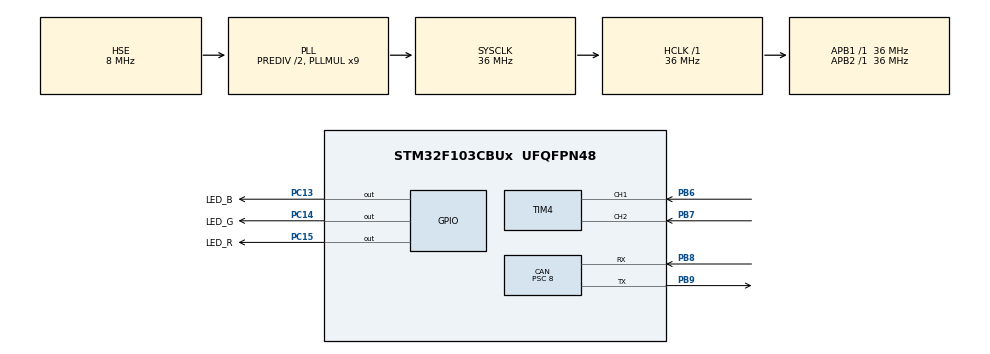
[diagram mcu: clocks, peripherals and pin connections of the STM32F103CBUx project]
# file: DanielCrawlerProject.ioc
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CAN.BS1=CAN_BS1_3TQ
CAN.BS2=CAN_BS2_5TQ
CAN.CalculateBaudRate=500000
CAN.CalculateTimeBit=1999.99
CAN.CalculateTimeQuantum=222.22222222222223
CAN.Prescaler=8
Mcu.Family=STM32F1
Mcu.Name=STM32F103CBUx
Mcu.Package=UFQFPN48
Mcu.UserConstants=MAX_ENCODER_COUNT,2000
NVIC.PriorityGroup=NVIC_PRIORITYGROUP_4
NVIC.TIM1_UP_IRQn=true\:4\:0\:true\:false\:true\:true\:true
NVIC.USB_LP_CAN1_RX0_IRQn=true\:0\:0\:false\:false\:true\:true\:true
PA13.Mode=Serial_Wire
PA13.Signal=SYS_JTMS-SWDIO
PA14.Mode=Serial_Wire
PA14.Signal=SYS_JTCK-SWCLK
PB6.Signal=S_TIM4_CH1
PB7.Signal=S_TIM4_CH2
PB8.Mode=CAN_Activate
PB8.Signal=CAN_RX
PB9.Mode=CAN_Activate
PB9.Signal=CAN_TX
PC13-TAMPER-RTC.GPIO_Label=LED_B
PC13-TAMPER-RTC.PinState=GPIO_PIN_RESET
PC13-TAMPER-RTC.Signal=GPIO_Output
PC14-OSC32_IN.GPIO_Label=LED_G
PC14-OSC32_IN.PinState=GPIO_PIN_RESET
PC14-OSC32_IN.Signal=GPIO_Output
PC15-OSC32_OUT.GPIO_Label=LED_R
PC15-OSC32_OUT.PinState=GPIO_PIN_RESET
PC15-OSC32_OUT.Signal=GPIO_Output
PD0-OSC_IN.Mode=HSE-External-Oscillator
PD0-OSC_IN.Signal=RCC_OSC_IN
PD1-OSC_OUT.Mode=HSE-External-Oscillator
PD1-OSC_OUT.Signal=RCC_OSC_OUT
ProjectManager.HeapSize=0x200
ProjectManager.StackSize=0x400
ProjectManager.TargetToolchain=STM32CubeIDE
RCC.AHBFreq_Value=36000000
RCC.APB1Freq_Value=36000000
RCC.APB1TimFreq_Value=36000000
RCC.APB2Freq_Value=36000000
RCC.APB2TimFreq_Value=36000000
RCC.HCLKFreq_Value=36000000
RCC.HSEDivPLL=RCC_HSE_PREDIV_DIV2
RCC.PLLMUL=RCC_PLL_MUL9
RCC.PLLSourceVirtual=RCC_PLLSOURCE_HSE
RCC.SYSCLKFreq_VALUE=36000000
RCC.SYSCLKSource=RCC_SYSCLKSOURCE_PLLCLK
RCC.USBFreq_Value=36000000
SH.S_TIM4_CH1.0=TIM4_CH1,Encoder_Interface
SH.S_TIM4_CH2.0=TIM4_CH2,Encoder_Interface
TIM1.Period=5000-1
TIM1.Prescaler=36-1
TIM4.EncoderMode=TIM_ENCODERMODE_TI12
TIM4.Period=MAX_ENCODER_COUNT
VP_TIM1_VS_ClockSourceINT.Mode=Internal
board=custom

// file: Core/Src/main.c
/* USER CODE BEGIN Header */
/**
  ******************************************************************************
  * @file           : main.c
  * @brief          : Main program body
  ******************************************************************************
  * @attention
  *
  * <h2><center>&copy; Copyright (c) 2020 STMicroelectronics.
  * All rights reserved.</center></h2>
  *
  * This software component is licensed by ST under BSD 3-Clause license,
  * the "License"; You may not use this file except in compliance with the
  * License. You may obtain a copy of the License at:
  *                        opensource.org/licenses/BSD-3-Clause
  *
  ******************************************************************************
  */
/* USER CODE END Header */
#include "main.h"
#include "can.h"
#include "tim.h"
#include "gpio.h"

/* USER CODE BEGIN Includes */
#include "cppmain.hpp"

/* USER CODE END Includes */

void SystemClock_Config(void);

int main(void)
{

  /* MCU Configuration--------------------------------------------------------*/

  /* Reset of all peripherals, Initializes the Flash interface and the Systick. */
  HAL_Init();

  /* Configure the system clock */
  SystemClock_Config();

  /* Initialize all configured peripherals */
  MX_GPIO_Init();
  MX_TIM1_Init();
  MX_TIM4_Init();
  MX_CAN_Init();
  /* USER CODE BEGIN 2 */
  setup();

  /* USER CODE END 2 */

  /* Infinite loop */
  /* USER CODE BEGIN WHILE */
  while (1)
  {
      loop();
    /* USER CODE END WHILE */

  }
}

void SystemClock_Config(void)
{
  RCC_OscInitTypeDef RCC_OscInitStruct = {0};
  RCC_ClkInitTypeDef RCC_ClkInitStruct = {0};

  /** Initializes the RCC Oscillators according to the specified parameters
  * in the RCC_OscInitTypeDef structure.
  */
  RCC_OscInitStruct.OscillatorType = RCC_OSCILLATORTYPE_HSE;
  RCC_OscInitStruct.HSEState = RCC_HSE_ON;
  RCC_OscInitStruct.HSEPredivValue = RCC_HSE_PREDIV_DIV2;
  RCC_OscInitStruct.HSIState = RCC_HSI_ON;
  RCC_OscInitStruct.PLL.PLLState = RCC_PLL_ON;
  RCC_OscInitStruct.PLL.PLLSource = RCC_PLLSOURCE_HSE;
  RCC_OscInitStruct.PLL.PLLMUL = RCC_PLL_MUL9;
  if (HAL_RCC_OscConfig(&RCC_OscInitStruct) != HAL_OK)
  {
    Error_Handler();
  }
  /** Initializes the CPU, AHB and APB buses clocks
  */
  RCC_ClkInitStruct.ClockType = RCC_CLOCKTYPE_HCLK|RCC_CLOCKTYPE_SYSCLK
                              |RCC_CLOCKTYPE_PCLK1|RCC_CLOCKTYPE_PCLK2;
  RCC_ClkInitStruct.SYSCLKSource = RCC_SYSCLKSOURCE_PLLCLK;
  RCC_ClkInitStruct.AHBCLKDivider = RCC_SYSCLK_DIV1;
  RCC_ClkInitStruct.APB1CLKDivider = RCC_HCLK_DIV1;
  RCC_ClkInitStruct.APB2CLKDivider = RCC_HCLK_DIV1;

  if (HAL_RCC_ClockConfig(&RCC_ClkInitStruct, FLASH_LATENCY_1) != HAL_OK)
  {
    Error_Handler();
  }
}

/* USER CODE BEGIN 4 */
//********************************
//    printfを使えるようにする
//********************************
int _write(int file, char *ptr, int len)
{
  int DataIdx;
  for (DataIdx = 0; DataIdx < len; DataIdx++) {
    ITM_SendChar(*ptr++);
  }
  return len;
}

/* USER CODE END 4 */

void Error_Handler(void)
{
}

/************************ (C) COPYRIGHT STMicroelectronics *****END OF FILE****/
